VERSION "oem_import_dbc_v0.1"

NS_ :

BS_:

BU_: AFC TeampoEVB TDA4VE AutoBox HMI_Simulation Vector__XXX

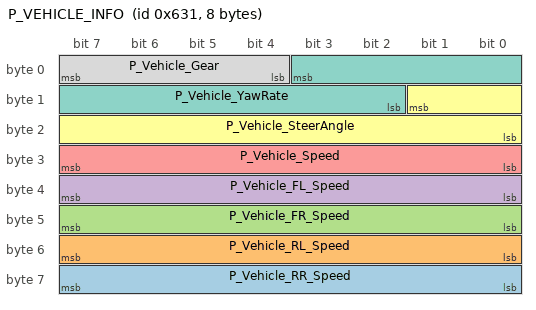
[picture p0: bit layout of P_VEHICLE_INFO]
BO_ 1585 P_VEHICLE_INFO: 8 AutoBox
 SG_ P_Vehicle_RR_Speed : 63|8@0+ (0.05,0) [0|12.7] "m/s" TDA4VE
 SG_ P_Vehicle_RL_Speed : 55|8@0+ (0.05,0) [0|12.7] "m/s" TDA4VE
 SG_ P_Vehicle_FR_Speed : 47|8@0+ (0.05,0) [0|12.7] "m/s" TDA4VE
 SG_ P_Vehicle_FL_Speed : 39|8@0+ (0.05,0) [0|12.7] "m/s" TDA4VE
 SG_ P_Vehicle_Speed : 31|8@0+ (0.05,0) [0|12.7] "m/s" TDA4VE
 SG_ P_Vehicle_SteerAngle : 9|10@0+ (4,-2048) [-2048|2044] "deg" TDA4VE
 SG_ P_Vehicle_YawRate : 3|10@0+ (0.2,-102.4) [-102.4|102.2] "deg/s" TDA4VE
 SG_ P_Vehicle_Gear : 7|4@0+ (1,0) [0|15] "" TDA4VE
